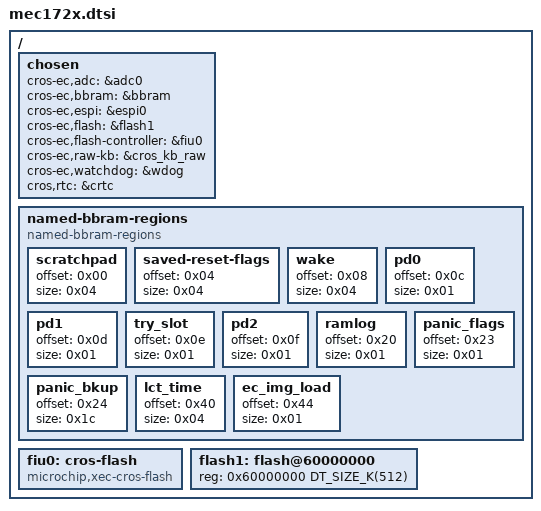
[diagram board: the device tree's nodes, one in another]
/* Copyright 2022 The ChromiumOS Authors
 * Use of this source code is governed by a BSD-style license that can be
 * found in the LICENSE file.
 */

#include <cros/binman.dtsi>
#include <microchip/mec172xnsz.dtsi>
#include <microchip/mec172x/mec172xnsz-pinctrl.dtsi>

/ {
	chosen {
		cros-ec,adc = &adc0;
		cros-ec,bbram = &bbram;
		cros-ec,espi = &espi0;
		cros-ec,flash = &flash1;
		cros-ec,flash-controller = &fiu0;
		cros-ec,raw-kb = &cros_kb_raw;
		cros-ec,watchdog = &wdog;
		cros,rtc = &crtc;
	};

	named-bbram-regions {
		compatible = "named-bbram-regions";

		scratchpad {
			offset = <0x00>;
			size = <0x04>;
		};
		saved-reset-flags {
			offset = <0x04>;
			size = <0x04>;
		};
		wake {
			offset = <0x08>;
			size = <0x04>;
		};
		pd0 {
			offset = <0x0c>;
			size = <0x01>;
		};
		pd1 {
			offset = <0x0d>;
			size = <0x01>;
		};
		try_slot {
			offset = <0x0e>;
			size = <0x01>;
		};
		pd2 {
			offset = <0x0f>;
			size = <0x01>;
		};
		ramlog {
			offset = <0x20>;
			size = <0x01>;
		};
		panic_flags {
			offset = <0x23>;
			size = <0x01>;
		};
		panic_bkup {
			offset = <0x24>;
			size = <0x1c>;
		};
		lct_time {
			offset = <0x40>;
			size = <0x04>;
		};
		ec_img_load {
			offset = <0x44>;
			size = <0x01>;
		};
	};

	fiu0: cros-flash {
		compatible = "microchip,xec-cros-flash";
	};

/*
 * flash:
 * Zephyr ChromeOS requires a separate node to describe the SPI flash for
 * internal and external flash devices.
 * The reason is:
 *	<cros_base>/ec/zephyr/Kconfig.flash

 * Kconfig item:

 * DT_CHOSEN_CROS_FLASH := cros-ec,flash

 * config PLATFORM_EC_FLASH_SIZE_BYTES
 *  hex "flash size"
 *	default $(dt_chosen_reg_size_hex,$(DT_CHOSEN_CROS_FLASH))
 *	help
 *	  Total size of writable flash.

 * The above Kconfig gets the flash size from the size of the Device Tree
 * register property.

 * Zephyr Flash SPI NOR driver uses a separate "size" property to specify
 * the flash size.
 */
	flash1: flash@60000000 {
		reg = <0x60000000 DT_SIZE_K(512)>;
	};
};
